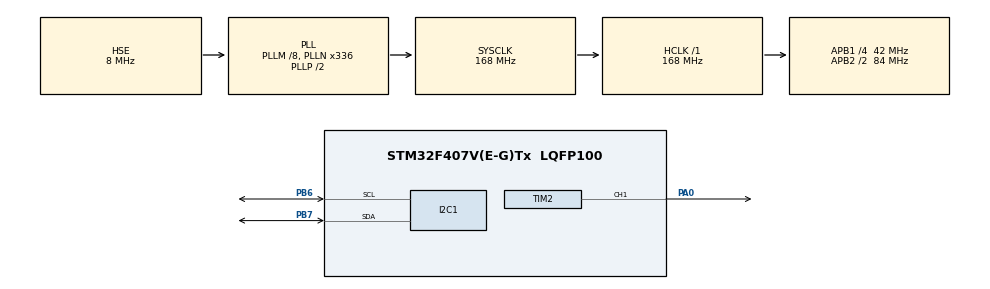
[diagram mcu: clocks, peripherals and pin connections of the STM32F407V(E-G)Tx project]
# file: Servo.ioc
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FREERTOS.Tasks01=defaultTask,0,128,StartDefaultTask,Default,NULL,Dynamic,NULL,NULL;ServoTask,0,128,ServoTask_int,Default,NULL,Dynamic,NULL,NULL
Mcu.Family=STM32F4
Mcu.Name=STM32F407V(E-G)Tx
Mcu.Package=LQFP100
NVIC.PriorityGroup=NVIC_PRIORITYGROUP_4
PA0-WKUP.Signal=S_TIM2_CH1_ETR
PA13.Mode=Serial_Wire
PA13.Signal=SYS_JTMS-SWDIO
PA14.Mode=Serial_Wire
PA14.Signal=SYS_JTCK-SWCLK
PB6.Mode=I2C
PB6.Signal=I2C1_SCL
PB7.Mode=I2C
PB7.Signal=I2C1_SDA
PH0-OSC_IN.Mode=HSE-External-Oscillator
PH0-OSC_IN.Signal=RCC_OSC_IN
PH1-OSC_OUT.Mode=HSE-External-Oscillator
PH1-OSC_OUT.Signal=RCC_OSC_OUT
ProjectManager.HeapSize=0x200
ProjectManager.StackSize=0x400
ProjectManager.TargetToolchain=MDK-ARM V5.32
RCC.48MHZClocksFreq_Value=84000000
RCC.AHBFreq_Value=168000000
RCC.APB1CLKDivider=RCC_HCLK_DIV4
RCC.APB1Freq_Value=42000000
RCC.APB1TimFreq_Value=84000000
RCC.APB2CLKDivider=RCC_HCLK_DIV2
RCC.APB2Freq_Value=84000000
RCC.APB2TimFreq_Value=168000000
RCC.CortexFreq_Value=168000000
RCC.HCLKFreq_Value=168000000
RCC.HSE_VALUE=8000000
RCC.HSI_VALUE=16000000
RCC.LSE_VALUE=32768
RCC.PLLM=8
RCC.PLLN=336
RCC.PLLSourceVirtual=RCC_PLLSOURCE_HSE
RCC.SYSCLKFreq_VALUE=168000000
RCC.SYSCLKSource=RCC_SYSCLKSOURCE_PLLCLK
RCC.VCOOutputFreq_Value=336000000
SH.S_TIM2_CH1_ETR.0=TIM2_CH1,PWM Generation1 CH1
TIM2.Channel-PWM\ Generation1\ CH1=TIM_CHANNEL_1
TIM2.Period=19999
TIM2.Prescaler=83
VP_FREERTOS_VS_CMSIS_V1.Mode=CMSIS_V1
VP_TIM2_VS_ClockSourceINT.Mode=Internal
board=custom

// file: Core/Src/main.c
/* USER CODE BEGIN Header */
/**
  ******************************************************************************
  * @file           : main.c
  * @brief          : Main program body
  ******************************************************************************
  * @attention
  *
  * Copyright (c) 2026 STMicroelectronics.
  * All rights reserved.
  *
  * This software is licensed under terms that can be found in the LICENSE file
  * in the root directory of this software component.
  * If no LICENSE file comes with this software, it is provided AS-IS.
  *
  ******************************************************************************
  */
/* USER CODE END Header */
#include "main.h"
#include "cmsis_os.h"

I2C_HandleTypeDef hi2c1;

TIM_HandleTypeDef htim2;

osThreadId defaultTaskHandle;
osThreadId ServoTaskHandle;

void SystemClock_Config(void);
static void MX_GPIO_Init(void);
static void MX_TIM2_Init(void);
static void MX_I2C1_Init(void);
void StartDefaultTask(void const * argument);
void ServoTask_int(void const * argument);

int main(void)
{

  /* MCU Configuration--------------------------------------------------------*/

  /* Reset of all peripherals, Initializes the Flash interface and the Systick. */
  HAL_Init();

  /* Configure the system clock */
  SystemClock_Config();

  /* Initialize all configured peripherals */
  MX_GPIO_Init();
  MX_TIM2_Init();
  MX_I2C1_Init();

  /* Create the thread(s) */
  /* definition and creation of defaultTask */
  osThreadDef(defaultTask, StartDefaultTask, osPriorityNormal, 0, 128);
  defaultTaskHandle = osThreadCreate(osThread(defaultTask), NULL);

  /* definition and creation of ServoTask */
  osThreadDef(ServoTask, ServoTask_int, osPriorityNormal, 0, 128);
  ServoTaskHandle = osThreadCreate(osThread(ServoTask), NULL);

  /* Start scheduler */
  osKernelStart();

  /* We should never get here as control is now taken by the scheduler */

  /* Infinite loop */
  while (1)
  {

  }
}

void SystemClock_Config(void)
{
  RCC_OscInitTypeDef RCC_OscInitStruct = {0};
  RCC_ClkInitTypeDef RCC_ClkInitStruct = {0};

  /** Configure the main internal regulator output voltage
  */
  __HAL_RCC_PWR_CLK_ENABLE();
  __HAL_PWR_VOLTAGESCALING_CONFIG(PWR_REGULATOR_VOLTAGE_SCALE1);

  /** Initializes the RCC Oscillators according to the specified parameters
  * in the RCC_OscInitTypeDef structure.
  */
  RCC_OscInitStruct.OscillatorType = RCC_OSCILLATORTYPE_HSE;
  RCC_OscInitStruct.HSEState = RCC_HSE_ON;
  RCC_OscInitStruct.PLL.PLLState = RCC_PLL_ON;
  RCC_OscInitStruct.PLL.PLLSource = RCC_PLLSOURCE_HSE;
  RCC_OscInitStruct.PLL.PLLM = 8;
  RCC_OscInitStruct.PLL.PLLN = 336;
  RCC_OscInitStruct.PLL.PLLP = RCC_PLLP_DIV2;
  RCC_OscInitStruct.PLL.PLLQ = 4;
  if (HAL_RCC_OscConfig(&RCC_OscInitStruct) != HAL_OK)
  {
    Error_Handler();
  }

  /** Initializes the CPU, AHB and APB buses clocks
  */
  RCC_ClkInitStruct.ClockType = RCC_CLOCKTYPE_HCLK|RCC_CLOCKTYPE_SYSCLK
                              |RCC_CLOCKTYPE_PCLK1|RCC_CLOCKTYPE_PCLK2;
  RCC_ClkInitStruct.SYSCLKSource = RCC_SYSCLKSOURCE_PLLCLK;
  RCC_ClkInitStruct.AHBCLKDivider = RCC_SYSCLK_DIV1;
  RCC_ClkInitStruct.APB1CLKDivider = RCC_HCLK_DIV4;
  RCC_ClkInitStruct.APB2CLKDivider = RCC_HCLK_DIV2;

  if (HAL_RCC_ClockConfig(&RCC_ClkInitStruct, FLASH_LATENCY_5) != HAL_OK)
  {
    Error_Handler();
  }
}

static void MX_I2C1_Init(void)
{

  hi2c1.Instance = I2C1;
  hi2c1.Init.ClockSpeed = 100000;
  hi2c1.Init.DutyCycle = I2C_DUTYCYCLE_2;
  hi2c1.Init.OwnAddress1 = 0;
  hi2c1.Init.AddressingMode = I2C_ADDRESSINGMODE_7BIT;
  hi2c1.Init.DualAddressMode = I2C_DUALADDRESS_DISABLE;
  hi2c1.Init.OwnAddress2 = 0;
  hi2c1.Init.GeneralCallMode = I2C_GENERALCALL_DISABLE;
  hi2c1.Init.NoStretchMode = I2C_NOSTRETCH_DISABLE;
  if (HAL_I2C_Init(&hi2c1) != HAL_OK)
  {
    Error_Handler();
  }

}

static void MX_TIM2_Init(void)
{

  TIM_ClockConfigTypeDef sClockSourceConfig = {0};
  TIM_MasterConfigTypeDef sMasterConfig = {0};
  TIM_OC_InitTypeDef sConfigOC = {0};

  htim2.Instance = TIM2;
  htim2.Init.Prescaler = 83;
  htim2.Init.CounterMode = TIM_COUNTERMODE_UP;
  htim2.Init.Period = 19999;
  htim2.Init.ClockDivision = TIM_CLOCKDIVISION_DIV1;
  htim2.Init.AutoReloadPreload = TIM_AUTORELOAD_PRELOAD_DISABLE;
  if (HAL_TIM_Base_Init(&htim2) != HAL_OK)
  {
    Error_Handler();
  }
  sClockSourceConfig.ClockSource = TIM_CLOCKSOURCE_INTERNAL;
  if (HAL_TIM_ConfigClockSource(&htim2, &sClockSourceConfig) != HAL_OK)
  {
    Error_Handler();
  }
  if (HAL_TIM_PWM_Init(&htim2) != HAL_OK)
  {
    Error_Handler();
  }
  sMasterConfig.MasterOutputTrigger = TIM_TRGO_RESET;
  sMasterConfig.MasterSlaveMode = TIM_MASTERSLAVEMODE_DISABLE;
  if (HAL_TIMEx_MasterConfigSynchronization(&htim2, &sMasterConfig) != HAL_OK)
  {
    Error_Handler();
  }
  sConfigOC.OCMode = TIM_OCMODE_PWM1;
  sConfigOC.Pulse = 0;
  sConfigOC.OCPolarity = TIM_OCPOLARITY_HIGH;
  sConfigOC.OCFastMode = TIM_OCFAST_DISABLE;
  if (HAL_TIM_PWM_ConfigChannel(&htim2, &sConfigOC, TIM_CHANNEL_1) != HAL_OK)
  {
    Error_Handler();
  }
  HAL_TIM_MspPostInit(&htim2);

}

static void MX_GPIO_Init(void)
{

  /* GPIO Ports Clock Enable */
  __HAL_RCC_GPIOH_CLK_ENABLE();
  __HAL_RCC_GPIOA_CLK_ENABLE();
  __HAL_RCC_GPIOB_CLK_ENABLE();

}

void StartDefaultTask(void const * argument)
{
  /* USER CODE BEGIN 5 */
	void tasks_manager(void);
  /* Infinite loop */
  for(;;)
  {
    osDelay(1);
  }
  /* USER CODE END 5 */
}

void ServoTask_int(void const * argument)
{
  /* USER CODE BEGIN ServoTask_int */
//  ServoTimer_Control();
	ServoPCA9685_Control();
  /* Infinite loop */
  for(;;)
  {
    osDelay(1);
  }
  /* USER CODE END ServoTask_int */
}

void Error_Handler(void)
{
  __disable_irq();
  while (1)
  {
  }
}
